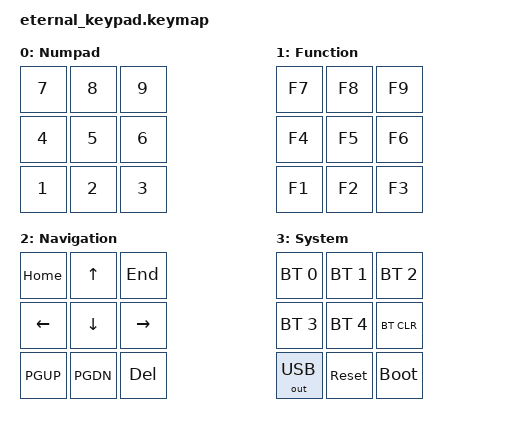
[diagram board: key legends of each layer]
/*
 * Copyright (c) 2022 The ZMK Contributors
 *
 * SPDX-License-Identifier: MIT
 */

#include <behaviors.dtsi>
#include <dt-bindings/zmk/keys.h>
#include <dt-bindings/zmk/bt.h>
#include <dt-bindings/zmk/outputs.h>

/ {
    chosen {
        zmk,kscan = &kscan0;
        zmk,matrix-transform = &default_transform;
        zmk,layer_names = "Numpad", "Function", "Navigation", "System";
    };

    behaviors {
        td_layer: tap_dance_layer {
            compatible = "zmk,behavior-tap-dance";
            label = "LAYER_CYCLE";
            #binding-cells = <0>;
            tapping-term-ms = <200>;
            bindings = <&to 0>, <&to 1>, <&to 2>, <&to 3>;
        };
    };

    sensors {
        compatible = "zmk,keymap-sensors";
        sensors = <&encoder>;
        triggers-per-rotation = <20>;
    };

    keymap {
        compatible = "zmk,keymap";

        default_layer {
            label = "Numpad";
            bindings = 
                &kp N7  &kp N8  &kp N9
                &kp N4  &kp N5  &kp N6
                &kp N1  &kp N2  &kp N3
            >;
            sensor-bindings = <&inc_dec_kp C_VOL_UP C_VOL_DN>;
        };

        function_layer {
            label = "Function";
            bindings = 
                &kp F7  &kp F8  &kp F9
                &kp F4  &kp F5  &kp F6
                &kp F1  &kp F2  &kp F3
            >;
            sensor-bindings = <&inc_dec_kp C_BRI_UP C_BRI_DN>;
        };

        navigation_layer {
            label = "Navigation";
            bindings = 
                &kp HOME  &kp UP    &kp END
                &kp LEFT  &kp DOWN  &kp RIGHT
                &kp PGUP  &kp PGDN  &kp DEL
            >;
            sensor-bindings = <&inc_dec_kp C_NEXT C_PREV>;
        };

        system_layer {
            label = "System";
            bindings = 
                &bt BT_SEL 0  &bt BT_SEL 1  &bt BT_SEL 2
                &bt BT_SEL 3  &bt BT_SEL 4  &bt BT_CLR
                &out OUT_USB  &sys_reset    &bootloader
            >;
            sensor-bindings = <&inc_dec_kp C_VOL_UP C_VOL_DN>;
        };
    };
};
